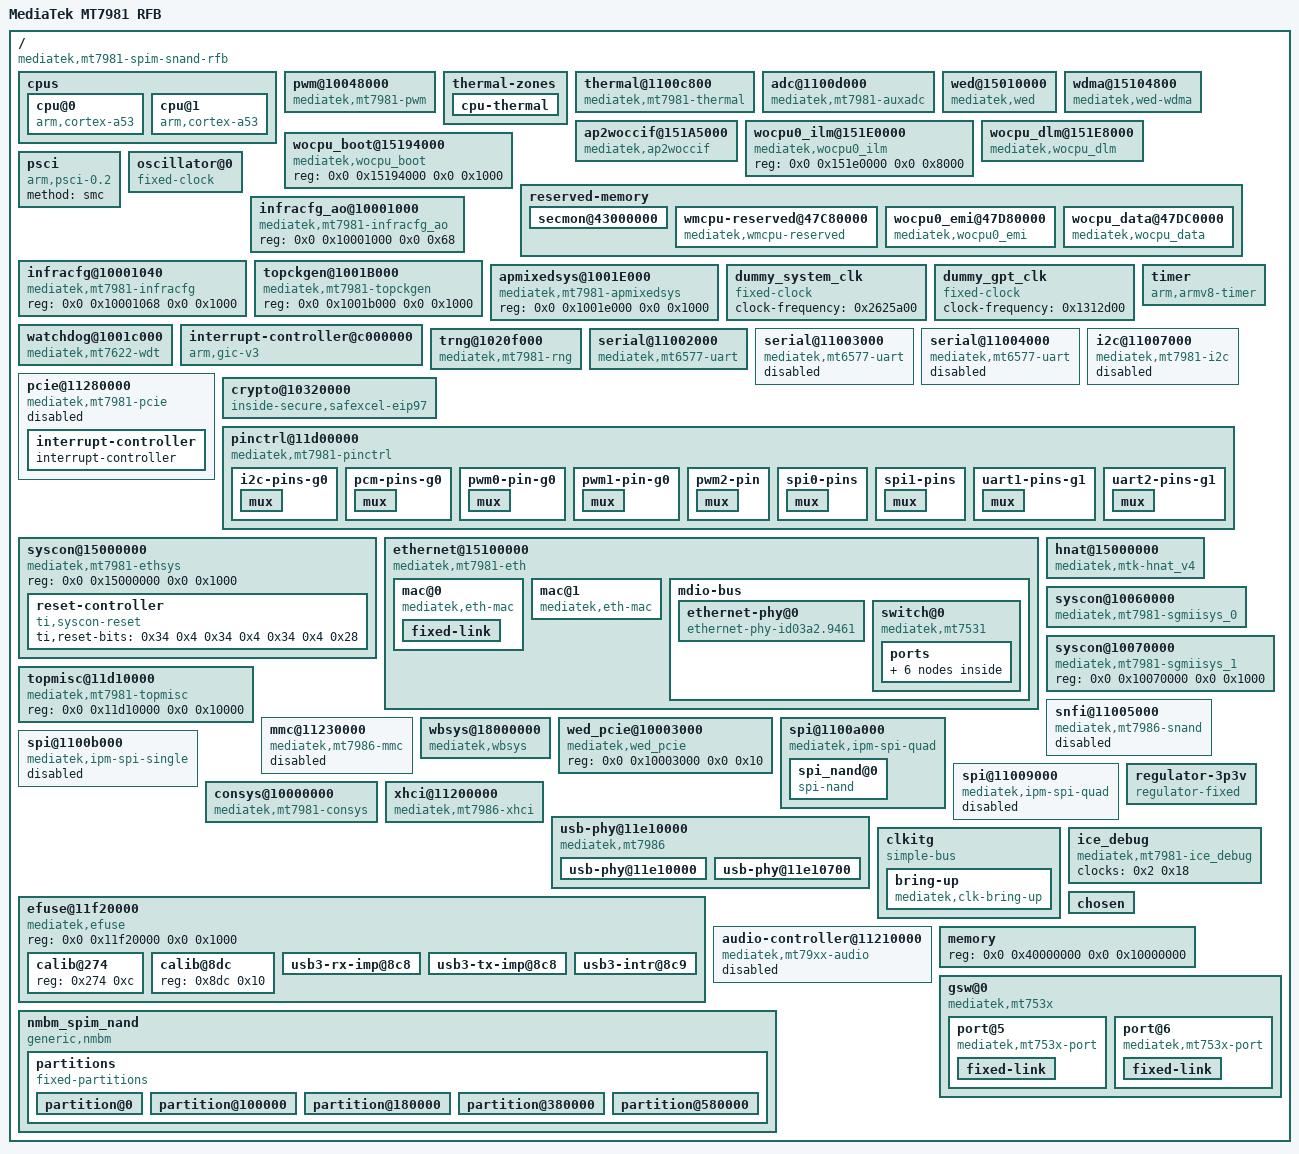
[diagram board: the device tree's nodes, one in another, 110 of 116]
/dts-v1/;

/ {
	compatible = "mediatek,mt7981-spim-snand-rfb";
	interrupt-parent = <0x1>;
	#address-cells = <0x2>;
	#size-cells = <0x2>;
	model = "MediaTek MT7981 RFB";
	cpus {
		#address-cells = <0x1>;
		#size-cells = <0x0>;
		cpu@0 {
			device_type = "cpu";
			compatible = "arm,cortex-a53";
			enable-method = "psci";
			reg = <0x0>;
		};
		cpu@1 {
			device_type = "cpu";
			compatible = "arm,cortex-a53";
			enable-method = "psci";
			reg = <0x1>;
		};
	};
	pwm@10048000 {
		compatible = "mediatek,mt7981-pwm";
		reg = <0x0 0x10048000 0x0 0x1000>;
		#pwm-cells = <0x2>;
		clocks = <0x2 0xd 0x2 0xc 0x2 0xe 0x2 0xf 0x2 0x10>;
		clock-names = "top", "main", "pwm1", "pwm2", "pwm3";
	};
	thermal-zones {
		cpu-thermal {
			polling-delay-passive = <0x3e8>;
			polling-delay = <0x3e8>;
			thermal-sensors = <0x3 0x0>;
		};
	};
	thermal@1100c800 {
		#thermal-sensor-cells = <0x1>;
		compatible = "mediatek,mt7981-thermal";
		reg = <0x0 0x1100c800 0x0 0x800>;
		interrupts = <0x0 0x8a 0x4>;
		clocks = <0x2 0x1c 0x2 0x2f 0x2 0x30>;
		clock-names = "therm", "auxadc", "adc_32k";
		mediatek,auxadc = <0x4>;
		mediatek,apmixedsys = <0x5>;
		nvmem-cells = <0x6>;
		nvmem-cell-names = "calibration-data";
		phandle = <0x3>;
	};
	adc@1100d000 {
		compatible = "mediatek,mt7981-auxadc", "mediatek,mt7622-auxadc";
		reg = <0x0 0x1100d000 0x0 0x1000>;
		clocks = <0x2 0x2f 0x2 0x30>;
		clock-names = "main", "32k";
		#io-channel-cells = <0x1>;
		phandle = <0x4>;
	};
	wed@15010000 {
		compatible = "mediatek,wed";
		wed_num = <0x2>;
		pci_slot_map = <0x0 0x1>;
		reg = <0x0 0x15010000 0x0 0x1000 0x0 0x15011000 0x0 0x1000>;
		interrupt-parent = <0x1>;
		interrupts = <0x0 0xcd 0x4 0x0 0xce 0x4>;
		dy_txbm_enable = "true";
		dy_txbm_budget = <0x8>;
		txbm_init_sz = <0x8>;
		txbm_max_sz = <0x20>;
		status = "okay";
	};
	wdma@15104800 {
		compatible = "mediatek,wed-wdma";
		reg = <0x0 0x15104800 0x0 0x400 0x0 0x15104c00 0x0 0x400>;
	};
	ap2woccif@151A5000 {
		compatible = "mediatek,ap2woccif";
		reg = <0x0 0x151a5000 0x0 0x1000 0x0 0x151ad000 0x0 0x1000>;
		interrupt-parent = <0x1>;
		interrupts = <0x0 0xd3 0x4 0x0 0xd4 0x4>;
	};
	wocpu0_ilm@151E0000 {
		compatible = "mediatek,wocpu0_ilm";
		reg = <0x0 0x151e0000 0x0 0x8000>;
	};
	wocpu_dlm@151E8000 {
		compatible = "mediatek,wocpu_dlm";
		reg = <0x0 0x151e8000 0x0 0x2000 0x0 0x151f8000 0x0 0x2000>;
		resets = <0x7 0x0>;
		reset-names = "wocpu_rst";
	};
	wocpu_boot@15194000 {
		compatible = "mediatek,wocpu_boot";
		reg = <0x0 0x15194000 0x0 0x1000>;
	};
	reserved-memory {
		#address-cells = <0x2>;
		#size-cells = <0x2>;
		ranges;
		secmon@43000000 {
			reg = <0x0 0x43000000 0x0 0x30000>;
			no-map;
		};
		wmcpu-reserved@47C80000 {
			compatible = "mediatek,wmcpu-reserved";
			no-map;
			reg = <0x0 0x47c80000 0x0 0x100000>;
			phandle = <0x16>;
		};
		wocpu0_emi@47D80000 {
			compatible = "mediatek,wocpu0_emi";
			no-map;
			reg = <0x0 0x47d80000 0x0 0x40000>;
			shared = <0x0>;
		};
		wocpu_data@47DC0000 {
			compatible = "mediatek,wocpu_data";
			no-map;
			reg = <0x0 0x47dc0000 0x0 0x240000>;
			shared = <0x1>;
		};
	};
	psci {
		compatible = "arm,psci-0.2";
		method = "smc";
	};
	oscillator@0 {
		compatible = "fixed-clock";
		#clock-cells = <0x0>;
		clock-frequency = <0x2625a00>;
		clock-output-names = "clkxtal";
		phandle = <0x1c>;
	};
	infracfg_ao@10001000 {
		compatible = "mediatek,mt7981-infracfg_ao", "syscon";
		reg = <0x0 0x10001000 0x0 0x68>;
		#clock-cells = <0x1>;
		phandle = <0x2>;
	};
	infracfg@10001040 {
		compatible = "mediatek,mt7981-infracfg", "syscon";
		reg = <0x0 0x10001068 0x0 0x1000>;
		#clock-cells = <0x1>;
		phandle = <0x9>;
	};
	topckgen@1001B000 {
		compatible = "mediatek,mt7981-topckgen", "syscon";
		reg = <0x0 0x1001b000 0x0 0x1000>;
		#clock-cells = <0x1>;
		phandle = <0x8>;
	};
	apmixedsys@1001E000 {
		compatible = "mediatek,mt7981-apmixedsys", "syscon";
		reg = <0x0 0x1001e000 0x0 0x1000>;
		#clock-cells = <0x1>;
		phandle = <0x5>;
	};
	dummy_system_clk {
		compatible = "fixed-clock";
		clock-frequency = <0x2625a00>;
		#clock-cells = <0x0>;
		phandle = <0x18>;
	};
	dummy_gpt_clk {
		compatible = "fixed-clock";
		clock-frequency = <0x1312d00>;
		#clock-cells = <0x0>;
	};
	timer {
		compatible = "arm,armv8-timer";
		interrupt-parent = <0x1>;
		clock-frequency = <0xc65d40>;
		interrupts = <0x1 0xd 0x8 0x1 0xe 0x8 0x1 0xb 0x8 0x1 0xa 0x8>;
	};
	watchdog@1001c000 {
		compatible = "mediatek,mt7622-wdt", "mediatek,mt6589-wdt";
		reg = <0x0 0x1001c000 0x0 0x1000>;
		interrupts = <0x0 0x6e 0x4>;
		#reset-cells = <0x1>;
		status = "okay";
	};
	interrupt-controller@c000000 {
		compatible = "arm,gic-v3";
		#interrupt-cells = <0x3>;
		interrupt-parent = <0x1>;
		interrupt-controller;
		reg = <0x0 0xc000000 0x0 0x40000 0x0 0xc080000 0x0 0x200000>;
		interrupts = <0x1 0x9 0x4>;
		phandle = <0x1>;
	};
	trng@1020f000 {
		compatible = "mediatek,mt7981-rng";
	};
	serial@11002000 {
		compatible = "mediatek,mt6577-uart";
		reg = <0x0 0x11002000 0x0 0x400>;
		interrupts = <0x0 0x7b 0x4>;
		clocks = <0x2 0x1e>;
		assigned-clocks = <0x8 0x50 0x2 0x0>;
		assigned-clock-parents = <0x8 0x0 0x9 0x1>;
		status = "okay";
	};
	serial@11003000 {
		compatible = "mediatek,mt6577-uart";
		reg = <0x0 0x11003000 0x0 0x400>;
		interrupts = <0x0 0x7c 0x4>;
		clocks = <0x2 0x1f>;
		assigned-clocks = <0x8 0x50 0x2 0x1>;
		assigned-clock-parents = <0x8 0x0 0x9 0x1>;
		status = "disabled";
	};
	serial@11004000 {
		compatible = "mediatek,mt6577-uart";
		reg = <0x0 0x11004000 0x0 0x400>;
		interrupts = <0x0 0x7d 0x4>;
		clocks = <0x2 0x20>;
		assigned-clocks = <0x8 0x50 0x2 0x2>;
		assigned-clock-parents = <0x8 0x0 0x9 0x1>;
		status = "disabled";
	};
	i2c@11007000 {
		compatible = "mediatek,mt7981-i2c";
		reg = <0x0 0x11007000 0x0 0x1000 0x0 0x10217080 0x0 0x80>;
		interrupts = <0x0 0x88 0x4>;
		clock-div = <0x1>;
		clocks = <0x2 0x1d 0x2 0x19>;
		clock-names = "main", "dma";
		#address-cells = <0x1>;
		#size-cells = <0x0>;
		status = "disabled";
	};
	pcie@11280000 {
		compatible = "mediatek,mt7981-pcie", "mediatek,mt7986-pcie";
		device_type = "pci";
		reg = <0x0 0x11280000 0x0 0x4000>;
		reg-names = "pcie-mac";
		#address-cells = <0x3>;
		#size-cells = <0x2>;
		interrupts = <0x0 0xa8 0x4>;
		bus-range = <0x0 0xff>;
		ranges = <0x82000000 0x0 0x20000000 0x0 0x20000000 0x0 0x10000000>;
		status = "disabled";
		clocks = <0x2 0x38 0x2 0x39 0x2 0x3a 0x2 0x3b>;
		phys = <0xa 0x2>;
		phy-names = "pcie-phy";
		#interrupt-cells = <0x1>;
		interrupt-map-mask = <0x0 0x0 0x0 0x7>;
		interrupt-map = <0x0 0x0 0x0 0x1 0xb 0x0 0x0 0x0 0x0 0x2 0xb 0x1 0x0 0x0 0x0 0x3 0xb 0x2 0x0 0x0 0x0 0x4 0xb 0x3>;
		interrupt-controller {
			interrupt-controller;
			#address-cells = <0x0>;
			#interrupt-cells = <0x1>;
			phandle = <0xb>;
		};
	};
	crypto@10320000 {
		compatible = "inside-secure,safexcel-eip97";
		reg = <0x0 0x10320000 0x0 0x40000>;
		interrupts = <0x0 0x74 0x4 0x0 0x75 0x4 0x0 0x76 0x4 0x0 0x77 0x4>;
		interrupt-names = "ring0", "ring1", "ring2", "ring3";
		clocks = <0x8 0x42>;
		clock-names = "top_eip97_ck";
		assigned-clocks = <0x8 0x63>;
		assigned-clock-parents = <0x8 0x15>;
	};
	pinctrl@11d00000 {
		compatible = "mediatek,mt7981-pinctrl";
		reg = <0x0 0x11d00000 0x0 0x1000 0x0 0x11c00000 0x0 0x1000 0x0 0x11c10000 0x0 0x1000 0x0 0x11d20000 0x0 0x1000 0x0 0x11e00000 0x0 0x1000 0x0 0x11e20000 0x0 0x1000 0x0 0x11f00000 0x0 0x1000 0x0 0x11f10000 0x0 0x1000 0x0 0x1000b000 0x0 0x1000>;
		reg-names = "gpio_base", "iocfg_rt_base", "iocfg_rm_base", "iocfg_rb_base", "iocfg_lb_base", "iocfg_bl_base", "iocfg_tm_base", "iocfg_tl_base", "eint";
		gpio-controller;
		#gpio-cells = <0x2>;
		gpio-ranges = <0xc 0x0 0x0 0x38>;
		interrupt-controller;
		interrupts = <0x0 0xe1 0x4>;
		interrupt-parent = <0x1>;
		#interrupt-cells = <0x2>;
		phandle = <0xc>;
		i2c-pins-g0 {
			mux {
				function = "i2c";
				groups = "i2c0_0";
			};
		};
		pcm-pins-g0 {
			mux {
				function = "pcm";
				groups = "pcm";
			};
		};
		pwm0-pin-g0 {
			mux {
				function = "pwm";
				groups = "pwm0_0";
			};
		};
		pwm1-pin-g0 {
			mux {
				function = "pwm";
				groups = "pwm1_0";
			};
		};
		pwm2-pin {
			mux {
				function = "pwm";
				groups = "pwm2";
			};
		};
		spi0-pins {
			phandle = <0x14>;
			mux {
				function = "spi";
				groups = "spi0", "spi0_wp_hold";
			};
		};
		spi1-pins {
			phandle = <0x15>;
			mux {
				function = "spi";
				groups = "spi1_1";
			};
		};
		uart1-pins-g1 {
			mux {
				function = "uart";
				groups = "uart1_1";
			};
		};
		uart2-pins-g1 {
			mux {
				function = "uart";
				groups = "uart2_1";
			};
		};
	};
	syscon@15000000 {
		#address-cells = <0x1>;
		#size-cells = <0x1>;
		compatible = "mediatek,mt7981-ethsys", "syscon";
		reg = <0x0 0x15000000 0x0 0x1000>;
		#clock-cells = <0x1>;
		#reset-cells = <0x1>;
		phandle = <0xd>;
		reset-controller {
			compatible = "ti,syscon-reset";
			#reset-cells = <0x1>;
			ti,reset-bits = <0x34 0x4 0x34 0x4 0x34 0x4 0x28>;
			phandle = <0x7>;
		};
	};
	ethernet@15100000 {
		compatible = "mediatek,mt7981-eth";
		reg = <0x0 0x15100000 0x0 0x80000>;
		interrupts = <0x0 0xc4 0x4 0x0 0xc5 0x4 0x0 0xc6 0x4 0x0 0xc7 0x4>;
		clocks = <0xd 0x0 0xd 0x1 0xd 0x2 0xd 0x3 0xe 0x0 0xe 0x1 0xe 0x2 0xe 0x3 0xf 0x0 0xf 0x1 0xf 0x2 0xf 0x3>;
		clock-names = "fe", "gp2", "gp1", "wocpu0", "sgmii_tx250m", "sgmii_rx250m", "sgmii_cdr_ref", "sgmii_cdr_fb", "sgmii2_tx250m", "sgmii2_rx250m", "sgmii2_cdr_ref", "sgmii2_cdr_fb";
		assigned-clocks = <0x8 0x60 0x8 0x61>;
		assigned-clock-parents = <0x8 0x1b 0x8 0x22>;
		mediatek,ethsys = <0xd>;
		mediatek,sgmiisys = <0xe 0xf>;
		mediatek,infracfg = <0x10>;
		#reset-cells = <0x1>;
		#address-cells = <0x1>;
		#size-cells = <0x0>;
		status = "okay";
		mac@0 {
			compatible = "mediatek,eth-mac";
			reg = <0x0>;
			phy-mode = "2500base-x";
			phandle = <0x13>;
			fixed-link {
				speed = <0x9c4>;
				full-duplex;
				pause;
			};
		};
		mac@1 {
			compatible = "mediatek,eth-mac";
			reg = <0x1>;
			phy-mode = "gmii";
			phy-handle = <0x11>;
		};
		mdio-bus {
			#address-cells = <0x1>;
			#size-cells = <0x0>;
			phandle = <0x1e>;
			ethernet-phy@0 {
				compatible = "ethernet-phy-id03a2.9461";
				reg = <0x0>;
				phy-mode = "gmii";
				nvmem-cells = <0x12>;
				nvmem-cell-names = "phy-cal-data";
				phandle = <0x11>;
			};
			switch@0 {
				compatible = "mediatek,mt7531";
				reg = <0x1f>;
				reset-gpios = <0xc 0x27 0x0>;
				ports {
					#address-cells = <0x1>;
					#size-cells = <0x0>;
					port@0 {
						reg = <0x0>;
						label = "lan1";
					};
					port@1 {
						reg = <0x1>;
						label = "lan2";
					};
					port@2 {
						reg = <0x2>;
						label = "lan3";
					};
					port@3 {
						reg = <0x3>;
						label = "lan4";
					};
					port@6 {
						reg = <0x6>;
						label = "cpu";
						ethernet = <0x13>;
						phy-mode = "2500base-x";
						fixed-link {
							speed = <0x9c4>;
							full-duplex;
							pause;
						};
					};
				};
			};
		};
	};
	hnat@15000000 {
		compatible = "mediatek,mtk-hnat_v4";
		reg = <0x0 0x15100000 0x0 0x80000>;
		resets = <0xd 0x0>;
		reset-names = "mtketh";
		status = "okay";
		mtketh-wan = "eth0.6";
		mtketh-lan = "eth0";
		mtketh-max-gmac = <0x2>;
	};
	syscon@10060000 {
		compatible = "mediatek,mt7981-sgmiisys_0", "syscon";
		reg = <0x0 0x10060000 0x0 0x1000>;
		pn_swap;
		#clock-cells = <0x1>;
		phandle = <0xe>;
	};
	syscon@10070000 {
		compatible = "mediatek,mt7981-sgmiisys_1", "syscon";
		reg = <0x0 0x10070000 0x0 0x1000>;
		#clock-cells = <0x1>;
		phandle = <0xf>;
	};
	topmisc@11d10000 {
		compatible = "mediatek,mt7981-topmisc", "syscon";
		reg = <0x0 0x11d10000 0x0 0x10000>;
		#clock-cells = <0x1>;
		phandle = <0x10>;
	};
	snfi@11005000 {
		compatible = "mediatek,mt7986-snand";
		reg = <0x0 0x11005000 0x0 0x1000 0x0 0x11006000 0x0 0x1000>;
		reg-names = "nfi", "ecc";
		interrupts = <0x0 0x79 0x4>;
		clocks = <0x2 0x24 0x2 0x23 0x2 0x25>;
		clock-names = "pad_clk", "nfi_clk", "nfi_hclk";
		assigned-clocks = <0x8 0x4d 0x8 0x4c>;
		assigned-clock-parents = <0x8 0x6 0x8 0x6>;
		#address-cells = <0x1>;
		#size-cells = <0x0>;
		status = "disabled";
	};
	mmc@11230000 {
		compatible = "mediatek,mt7986-mmc", "mediatek,mt7981-mmc";
		reg = <0x0 0x11230000 0x0 0x1000 0x0 0x11c20000 0x0 0x1000>;
		interrupts = <0x0 0x8f 0x4>;
		clocks = <0x8 0x33 0x8 0x34 0x2 0x2b>;
		assigned-clocks = <0x8 0x54 0x8 0x55>;
		assigned-clock-parents = <0x8 0x2 0x8 0x1c>;
		clock-names = "source", "hclk", "source_cg";
		status = "disabled";
	};
	wbsys@18000000 {
		compatible = "mediatek,wbsys";
		reg = <0x0 0x18000000 0x0 0x1000000>;
		interrupts = <0x0 0xd5 0x4 0x0 0xd6 0x4 0x0 0xd7 0x4 0x0 0xd8 0x4>;
		chip_id = <0x7981>;
	};
	wed_pcie@10003000 {
		compatible = "mediatek,wed_pcie";
		reg = <0x0 0x10003000 0x0 0x10>;
	};
	spi@1100a000 {
		compatible = "mediatek,ipm-spi-quad";
		reg = <0x0 0x1100a000 0x0 0x100>;
		interrupts = <0x0 0x8c 0x4>;
		clocks = <0x8 0x2 0x8 0x4e 0x2 0x26 0x2 0x28>;
		clock-names = "parent-clk", "sel-clk", "spi-clk", "spi-hclk";
		status = "okay";
		pinctrl-names = "default";
		pinctrl-0 = <0x14>;
		spi_nand@0 {
			#address-cells = <0x1>;
			#size-cells = <0x1>;
			compatible = "spi-nand";
			reg = <0x0>;
			spi-max-frequency = <0x2625a00>;
			spi-tx-buswidth = <0x4>;
			spi-rx-buswidth = <0x4>;
			phandle = <0x1d>;
		};
	};
	spi@1100b000 {
		compatible = "mediatek,ipm-spi-single";
		reg = <0x0 0x1100b000 0x0 0x100>;
		interrupts = <0x0 0x8d 0x4>;
		clocks = <0x8 0x2 0x8 0x4f 0x2 0x27 0x2 0x29>;
		clock-names = "parent-clk", "sel-clk", "spi-clk", "spi-hclk";
		status = "disabled";
		pinctrl-names = "default";
		pinctrl-0 = <0x15>;
	};
	spi@11009000 {
		compatible = "mediatek,ipm-spi-quad";
		reg = <0x0 0x11009000 0x0 0x100>;
		interrupts = <0x0 0x8e 0x4>;
		clocks = <0x8 0x2 0x8 0x4e 0x2 0x21 0x2 0x22>;
		clock-names = "parent-clk", "sel-clk", "spi-clk", "spi-hclk";
		status = "disabled";
	};
	consys@10000000 {
		compatible = "mediatek,mt7981-consys";
		reg = <0x0 0x10000000 0x0 0x8600000>;
		memory-region = <0x16>;
	};
	xhci@11200000 {
		compatible = "mediatek,mt7986-xhci", "mediatek,mtk-xhci";
		reg = <0x0 0x11200000 0x0 0x2e00 0x0 0x11203e00 0x0 0x100>;
		reg-names = "mac", "ippc";
		interrupts = <0x0 0xad 0x4>;
		phys = <0x17 0x3 0xa 0x4>;
		clocks = <0x18 0x18 0x18 0x18 0x18>;
		clock-names = "sys_ck", "xhci_ck", "ref_ck", "mcu_ck", "dma_ck";
		#address-cells = <0x2>;
		#size-cells = <0x2>;
		mediatek,u3p-dis-msk = <0x0>;
		status = "okay";
	};
	usb-phy@11e10000 {
		compatible = "mediatek,mt7986", "mediatek,generic-tphy-v2";
		#address-cells = <0x2>;
		#size-cells = <0x2>;
		ranges;
		status = "okay";
		usb-phy@11e10000 {
			reg = <0x0 0x11e10000 0x0 0x700>;
			clocks = <0x18>;
			clock-names = "ref";
			#phy-cells = <0x1>;
			status = "okay";
			phandle = <0x17>;
		};
		usb-phy@11e10700 {
			reg = <0x0 0x11e10700 0x0 0x900>;
			clocks = <0x18>;
			clock-names = "ref";
			#phy-cells = <0x1>;
			mediatek,syscon-type = <0x10 0x218 0x0>;
			nvmem-cells = <0x19 0x1a 0x1b>;
			nvmem-cell-names = "intr", "rx_imp", "tx_imp";
			status = "okay";
			phandle = <0xa>;
		};
	};
	regulator-3p3v {
		compatible = "regulator-fixed";
		regulator-name = "fixed-3.3V";
		regulator-min-microvolt = <0x325aa0>;
		regulator-max-microvolt = <0x325aa0>;
		regulator-boot-on;
		regulator-always-on;
	};
	clkitg {
		compatible = "simple-bus";
		bring-up {
			compatible = "mediatek,clk-bring-up";
			clocks = <0x5 0x0 0x5 0x1 0x5 0x2 0x5 0x3 0x5 0x4 0x5 0x5 0x5 0x6 0x5 0x7 0x9 0x0 0x1c 0x9 0x2 0x9 0x3 0x9 0x4 0x1c 0x9 0x6 0x9 0x7 0x1c 0x1c 0x1c 0x1c 0x9 0xc 0x9 0xd 0x9 0xe 0x9 0xf 0x9 0x10 0x9 0x11 0x1c 0x1c 0x1c 0x1c 0x1c 0x9 0x17 0x9 0x18 0x9 0x1a 0x9 0x1b 0x9 0x1c 0x9 0x1d 0x9 0x1e 0x9 0x1f 0x9 0x20 0x9 0x21 0x1c 0x9 0x23 0x1c 0x1c 0x1c 0x1c 0x1c 0x1c 0x1c 0x1c 0x1c 0x2 0xb 0x1c 0x1c 0x1c 0x1c 0x2 0x11 0x1c 0x1c 0x1c 0x1c 0x1c 0x2 0x17 0x1c 0x2 0x19 0x2 0x1a 0x2 0x1b 0x1c 0x1c 0x1c 0x1c 0x1c 0x1c 0x1c 0x1c 0x1c 0x1c 0x1c 0x1c 0x1c 0x1c 0x2 0x2a 0x2 0x2b 0x2 0x2c 0x2 0x2d 0x2 0x2e 0x1c 0x1c 0x2 0x31 0x2 0x32 0x2 0x33 0x2 0x34 0x2 0x35 0x2 0x36 0x2 0x37 0x1c 0x1c 0x1c 0x8 0x1 0x1c 0x8 0x5 0x8 0x6 0x8 0x7 0x8 0x4 0x8 0x9 0x8 0xc 0x8 0xf 0x8 0x10 0x8 0x12 0x8 0x14 0x8 0x15 0x8 0x16 0x8 0x17 0x8 0x19 0x8 0x1a 0x1c 0x8 0x1d 0x8 0x1e 0x8 0x21 0x1c 0x8 0x24 0x8 0x25 0x1c 0x8 0x29 0x8 0x26 0x8 0x2b 0x8 0x2a 0x1c 0x8 0x31 0x1c 0x1c 0x1c 0x8 0x56 0x8 0x37 0x8 0x3d 0x8 0x3e 0x8 0x3f 0x8 0x45 0x8 0x41 0x8 0x46 0x8 0x47 0x8 0x48 0x8 0x49 0x8 0x4a 0x8 0x3a 0x1c 0x1c 0x1c 0x1c 0x8 0x52 0x1c 0x1c 0x1c 0x8 0x56 0x8 0x57 0x8 0x58 0x8 0x59 0x8 0x5a 0x8 0x5b 0x8 0x5c 0x8 0x5d 0x8 0x5e 0x8 0x5f 0x1c 0x1c 0x8 0x62 0x8 0x5e 0x1c 0x8 0x64 0x8 0x56 0x8 0x69 0x8 0x6a 0x8 0x6b 0x8 0x6c>;
			clock-names = "0", "1", "2", "3", "4", "5", "6", "7", "8", "9", "10", "11", "12", "13", "14", "15", "16", "17", "18", "19", "20", "21", "22", "23", "24", "25", "26", "27", "28", "29", "30", "31", "32", "33", "34", "35", "36", "37", "38", "39", "40", "41", "42", "43", "44", "45", "46", "47", "48", "49", "50", "51", "52", "53", "54", "55", "56", "57", "58", "59", "60", "61", "62", "63", "64", "65", "66", "67", "68", "69", "70", "71", "72", "73", "74", "75", "76", "77", "78", "79", "80", "81", "82", "83", "84", "85", "86", "87", "88", "89", "90", "91", "92", "93", "94", "95", "96", "97", "98", "99", "100", "101", "102", "103", "104", "105", "106", "107", "108", "109", "110", "111", "112", "113", "114", "115", "116", "117", "118", "119", "120", "121", "122", "123", "124", "125", "126", "127", "128", "129", "130", "131", "132", "133", "134", "135", "136", "137", "138", "139", "140", "141", "142", "143", "144", "145", "146", "147", "148", "149", "150", "151", "152", "153", "154", "155", "156", "157", "158", "159", "160", "161", "162", "163", "164", "165", "166", "167", "168", "169", "170", "171", "172", "173", "174", "175", "176", "177", "178", "179", "180", "181", "182", "183";
		};
	};
	efuse@11f20000 {
		compatible = "mediatek,efuse";
		reg = <0x0 0x11f20000 0x0 0x1000>;
		#address-cells = <0x1>;
		#size-cells = <0x1>;
		calib@274 {
			reg = <0x274 0xc>;
			phandle = <0x6>;
		};
		calib@8dc {
			reg = <0x8dc 0x10>;
			phandle = <0x12>;
		};
		usb3-rx-imp@8c8 {
			reg = <0x8c8 0x1>;
			bits = <0x0 0x5>;
			phandle = <0x1a>;
		};
		usb3-tx-imp@8c8 {
			reg = <0x8c8 0x2>;
			bits = <0x5 0x5>;
			phandle = <0x1b>;
		};
		usb3-intr@8c9 {
			reg = <0x8c9 0x1>;
			bits = <0x2 0x6>;
			phandle = <0x19>;
		};
	};
	audio-controller@11210000 {
		compatible = "mediatek,mt79xx-audio";
		reg = <0x0 0x11210000 0x0 0x9000>;
		interrupts = <0x0 0x6a 0x4>;
		clocks = <0x2 0x12 0x2 0x13 0x2 0x14 0x2 0x15 0x2 0x16 0x8 0x65>;
		clock-names = "aud_bus_ck", "aud_26m_ck", "aud_l_ck", "aud_aud_ck", "aud_eg2_ck", "aud_sel";
		assigned-clocks = <0x8 0x65 0x8 0x66 0x8 0x67 0x8 0x68>;
		assigned-clock-parents = <0x8 0x10 0x8 0x12 0x8 0x10 0x8 0x12>;
		status = "disabled";
	};
	ice_debug {
		compatible = "mediatek,mt7981-ice_debug", "mediatek,mt2701-ice_debug";
		clocks = <0x2 0x18>;
		clock-names = "ice_dbg";
	};
	chosen {
		bootargs = "console=ttyS0,115200n1 loglevel=8  \t\t\t\tearlycon=uart8250,mmio32,0x11002000";
	};
	memory {
		reg = <0x0 0x40000000 0x0 0x10000000>;
	};
	nmbm_spim_nand {
		compatible = "generic,nmbm";
		#address-cells = <0x1>;
		#size-cells = <0x1>;
		lower-mtd-device = <0x1d>;
		forced-create;
		partitions {
			compatible = "fixed-partitions";
			#address-cells = <0x1>;
			#size-cells = <0x1>;
			partition@0 {
				label = "BL2";
				reg = <0x0 0x100000>;
				read-only;
			};
			partition@100000 {
				label = "u-boot-env";
				reg = <0x100000 0x80000>;
			};
			partition@180000 {
				label = "Factory";
				reg = <0x180000 0x200000>;
			};
			partition@380000 {
				label = "FIP";
				reg = <0x380000 0x200000>;
			};
			partition@580000 {
				label = "ubi";
				reg = <0x580000 0x4000000>;
			};
		};
	};
	gsw@0 {
		compatible = "mediatek,mt753x";
		mediatek,ethsys = <0xd>;
		#address-cells = <0x1>;
		#size-cells = <0x0>;
		mediatek,mdio = <0x1e>;
		mediatek,portmap = "llllw";
		mediatek,mdio_master_pinmux = <0x0>;
		reset-gpios = <0xc 0x27 0x0>;
		interrupt-parent = <0xc>;
		interrupts = <0x35 0x4>;
		status = "okay";
		port@5 {
			compatible = "mediatek,mt753x-port";
			reg = <0x5>;
			phy-mode = "rgmii";
			fixed-link {
				speed = <0x3e8>;
				full-duplex;
			};
		};
		port@6 {
			compatible = "mediatek,mt753x-port";
			reg = <0x6>;
			phy-mode = "sgmii";
			fixed-link {
				speed = <0x9c4>;
				full-duplex;
			};
		};
	};
};
